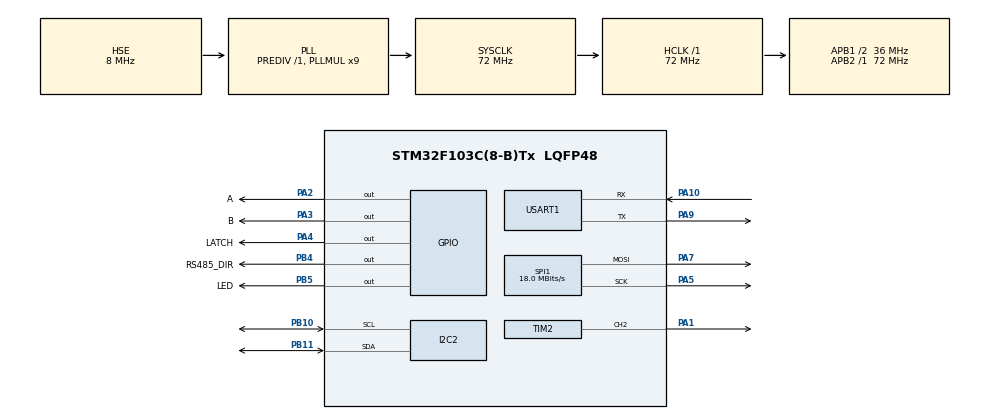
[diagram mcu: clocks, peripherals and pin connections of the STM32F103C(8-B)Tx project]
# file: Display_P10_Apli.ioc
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Dma.Request0=USART1_RX
Dma.USART1_RX.0.Direction=DMA_PERIPH_TO_MEMORY
Dma.USART1_RX.0.Instance=DMA1_Channel5
Dma.USART1_RX.0.MemDataAlignment=DMA_MDATAALIGN_BYTE
Dma.USART1_RX.0.MemInc=DMA_MINC_ENABLE
Dma.USART1_RX.0.Mode=DMA_NORMAL
Dma.USART1_RX.0.PeriphDataAlignment=DMA_PDATAALIGN_BYTE
Dma.USART1_RX.0.PeriphInc=DMA_PINC_DISABLE
Dma.USART1_RX.0.Priority=DMA_PRIORITY_LOW
FREERTOS.MEMORY_ALLOCATION=0
FREERTOS.Tasks01=mainTask,0,128,display_p10_main_task_entry,As weak,NULL,Dynamic,NULL,NULL;p10Task,0,256,display_p10_udapte_task_entry,As weak,NULL,Dynamic,NULL,NULL;modbusServer,-3,256,modbusServerRTU_Task,As weak,NULL,Dynamic,NULL,NULL
FREERTOS.configTICK_RATE_HZ=1000
FREERTOS.configTOTAL_HEAP_SIZE=10240
FREERTOS.configUSE_NEWLIB_REENTRANT=1
I2C2.I2C_Mode=I2C_Fast
Mcu.Family=STM32F1
Mcu.Name=STM32F103C(8-B)Tx
Mcu.Package=LQFP48
NVIC.DMA1_Channel5_IRQn=true\:5\:0\:false\:false\:true\:true\:false\:true\:true
NVIC.PriorityGroup=NVIC_PRIORITYGROUP_4
NVIC.TIM4_IRQn=true\:5\:0\:false\:false\:true\:true\:true\:true\:true
NVIC.USART1_IRQn=true\:5\:0\:false\:false\:true\:true\:true\:true\:true
PA1.Signal=S_TIM2_CH2
PA10.Mode=Asynchronous
PA10.Signal=USART1_RX
PA11.GPIO_Label=OE
PA11.Signal=S_TIM1_CH4
PA13.Mode=Serial_Wire
PA13.Signal=SYS_JTMS-SWDIO
PA14.Mode=Serial_Wire
PA14.Signal=SYS_JTCK-SWCLK
PA2.GPIO_Label=A
PA2.Signal=GPIO_Output
PA3.GPIO_Label=B
PA3.Signal=GPIO_Output
PA4.GPIO_Label=LATCH
PA4.Signal=GPIO_Output
PA5.Mode=TX_Only_Simplex_Unidirect_Master
PA5.Signal=SPI1_SCK
PA7.Mode=TX_Only_Simplex_Unidirect_Master
PA7.Signal=SPI1_MOSI
PA9.Mode=Asynchronous
PA9.Signal=USART1_TX
PB10.Mode=I2C
PB10.Signal=I2C2_SCL
PB11.Mode=I2C
PB11.Signal=I2C2_SDA
PB4.GPIO_Label=RS485_DIR
PB4.Signal=GPIO_Output
PB5.GPIO_Label=LED
PB5.Signal=GPIO_Output
PD0-OSC_IN.Mode=HSE-External-Oscillator
PD0-OSC_IN.Signal=RCC_OSC_IN
PD1-OSC_OUT.Mode=HSE-External-Oscillator
PD1-OSC_OUT.Signal=RCC_OSC_OUT
ProjectManager.HeapSize=0x200
ProjectManager.StackSize=0x400
ProjectManager.TargetToolchain=STM32CubeIDE
RCC.AHBFreq_Value=72000000
RCC.APB1CLKDivider=RCC_HCLK_DIV2
RCC.APB1Freq_Value=36000000
RCC.APB1TimFreq_Value=72000000
RCC.APB2Freq_Value=72000000
RCC.APB2TimFreq_Value=72000000
RCC.HCLKFreq_Value=72000000
RCC.PLLMUL=RCC_PLL_MUL9
RCC.PLLSourceVirtual=RCC_PLLSOURCE_HSE
RCC.SYSCLKFreq_VALUE=72000000
RCC.SYSCLKSource=RCC_SYSCLKSOURCE_PLLCLK
RCC.USBFreq_Value=72000000
SH.S_TIM1_CH4.0=TIM1_CH4
SH.S_TIM2_CH2.0=TIM2_CH2,PWM Generation2 CH2
SPI1.BaudRatePrescaler=SPI_BAUDRATEPRESCALER_4
SPI1.CalculateBaudRate=18.0 MBits/s
SPI1.Direction=SPI_DIRECTION_2LINES
SPI1.Mode=SPI_MODE_MASTER
SPI1.VirtualType=VM_MASTER
TIM2.Channel-PWM\ Generation2\ CH2=TIM_CHANNEL_2
TIM2.Period=999
TIM2.Prescaler=71
TIM4.Period=1999
TIM4.Prescaler=71
USART1.VirtualMode=VM_ASYNC
VP_FREERTOS_VS_CMSIS_V1.Mode=CMSIS_V1
VP_TIM4_VS_ClockSourceINT.Mode=Internal
board=custom

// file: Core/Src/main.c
/* USER CODE BEGIN Header */
/**
  ******************************************************************************
  * @file           : main.c
  * @brief          : Main program body
  ******************************************************************************
  * @attention
  *
  * Copyright (c) 2024 STMicroelectronics.
  * All rights reserved.
  *
  * This software is licensed under terms that can be found in the LICENSE file
  * in the root directory of this software component.
  * If no LICENSE file comes with this software, it is provided AS-IS.
  *
  ******************************************************************************
  */
/* USER CODE END Header */
#include "main.h"
#include "cmsis_os.h"
#include "dma.h"
#include "i2c.h"
#include "spi.h"
#include "tim.h"
#include "usart.h"
#include "gpio.h"

/* USER CODE BEGIN Includes */
#include "lwprintf.h"
/* USER CODE END Includes */

void SystemClock_Config(void);
void MX_FREERTOS_Init(void);

/* USER CODE BEGIN 0 */
extern int dmd_lwprintf_out(int ch, lwprintf_t* lwp);
/* USER CODE END 0 */

int main(void)
{

  /* MCU Configuration--------------------------------------------------------*/

  /* Reset of all peripherals, Initializes the Flash interface and the Systick. */
  HAL_Init();

  /* Configure the system clock */
  SystemClock_Config();

  /* Initialize all configured peripherals */
  MX_GPIO_Init();
  MX_DMA_Init();
  MX_I2C2_Init();
  MX_SPI1_Init();
  MX_TIM4_Init();
  MX_USART1_UART_Init();
  MX_TIM2_Init();
  /* USER CODE BEGIN 2 */
  lwprintf_init(dmd_lwprintf_out);
  /* USER CODE END 2 */

  /* Call init function for freertos objects (in cmsis_os2.c) */
  MX_FREERTOS_Init();

  /* Start scheduler */
  osKernelStart();

  /* We should never get here as control is now taken by the scheduler */

  /* Infinite loop */
  while (1)
  {

  }
}

void SystemClock_Config(void)
{
  RCC_OscInitTypeDef RCC_OscInitStruct = {0};
  RCC_ClkInitTypeDef RCC_ClkInitStruct = {0};

  /** Initializes the RCC Oscillators according to the specified parameters
  * in the RCC_OscInitTypeDef structure.
  */
  RCC_OscInitStruct.OscillatorType = RCC_OSCILLATORTYPE_HSE;
  RCC_OscInitStruct.HSEState = RCC_HSE_ON;
  RCC_OscInitStruct.HSEPredivValue = RCC_HSE_PREDIV_DIV1;
  RCC_OscInitStruct.HSIState = RCC_HSI_ON;
  RCC_OscInitStruct.PLL.PLLState = RCC_PLL_ON;
  RCC_OscInitStruct.PLL.PLLSource = RCC_PLLSOURCE_HSE;
  RCC_OscInitStruct.PLL.PLLMUL = RCC_PLL_MUL9;
  if (HAL_RCC_OscConfig(&RCC_OscInitStruct) != HAL_OK)
  {
    Error_Handler();
  }

  /** Initializes the CPU, AHB and APB buses clocks
  */
  RCC_ClkInitStruct.ClockType = RCC_CLOCKTYPE_HCLK|RCC_CLOCKTYPE_SYSCLK
                              |RCC_CLOCKTYPE_PCLK1|RCC_CLOCKTYPE_PCLK2;
  RCC_ClkInitStruct.SYSCLKSource = RCC_SYSCLKSOURCE_PLLCLK;
  RCC_ClkInitStruct.AHBCLKDivider = RCC_SYSCLK_DIV1;
  RCC_ClkInitStruct.APB1CLKDivider = RCC_HCLK_DIV2;
  RCC_ClkInitStruct.APB2CLKDivider = RCC_HCLK_DIV1;

  if (HAL_RCC_ClockConfig(&RCC_ClkInitStruct, FLASH_LATENCY_2) != HAL_OK)
  {
    Error_Handler();
  }
}

void Error_Handler(void)
{
  __disable_irq();
  while (1)
  {
  }
}

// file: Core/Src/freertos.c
/* USER CODE BEGIN Header */
/**
  ******************************************************************************
  * File Name          : freertos.c
  * Description        : Code for freertos applications
  ******************************************************************************
  * @attention
  *
  * Copyright (c) 2024 STMicroelectronics.
  * All rights reserved.
  *
  * This software is licensed under terms that can be found in the LICENSE file
  * in the root directory of this software component.
  * If no LICENSE file comes with this software, it is provided AS-IS.
  *
  ******************************************************************************
  */
/* USER CODE END Header */

#include "FreeRTOS.h"
#include "task.h"
#include "main.h"
#include "cmsis_os.h"

osThreadId mainTaskHandle;
osThreadId p10TaskHandle;
osThreadId modbusServerHandle;

/* USER CODE BEGIN FunctionPrototypes */
SemaphoreHandle_t p10_update;
/* USER CODE END FunctionPrototypes */

void display_p10_main_task_entry(void const * argument);
void display_p10_udapte_task_entry(void const * argument);
void modbusServerRTU_Task(void const * argument);

void MX_FREERTOS_Init(void); /* (MISRA C 2004 rule 8.1) */

void MX_FREERTOS_Init(void) {
  /* USER CODE BEGIN Init */
	p10_update = xSemaphoreCreateBinary();
  /* USER CODE END Init */

  /* Create the thread(s) */
  /* definition and creation of mainTask */
  osThreadDef(mainTask, display_p10_main_task_entry, osPriorityAboveNormal, 0, 128);
  mainTaskHandle = osThreadCreate(osThread(mainTask), NULL);

  /* definition and creation of p10Task */
  osThreadDef(p10Task, display_p10_udapte_task_entry, osPriorityNormal, 0, 256);
  p10TaskHandle = osThreadCreate(osThread(p10Task), NULL);

  /* definition and creation of modbusServer */
  osThreadDef(modbusServer, modbusServerRTU_Task, osPriorityLow, 0, 256);
  modbusServerHandle = osThreadCreate(osThread(modbusServer), NULL);

}

__weak void display_p10_main_task_entry(void const * argument)
{
  for(;;)
  {
    osDelay(1);
  }
}

__weak void display_p10_udapte_task_entry(void const * argument)
{
  for(;;)
  {
    osDelay(1);
  }
}

__weak void modbusServerRTU_Task(void const * argument)
{
  for(;;)
  {
    osDelay(1);
  }
}
